# nrf7140_wificore register map
Vendor: Nordic Semiconductor; Series: nRF71; File version: 1
Registers are 32-bit, read-write, reset 0x0 unless marked. A register's access mark holds for its fields unless they carry their own. Offsets are from the block's base; [hi:lo] are bit positions; lines under a group give offsets from that group; {n}, {i} and the like mark numbered series.

## RPUPHY (part 6 of 8) — WIFICore RPU PHY peripherals
Base 0x48080000; alternate view of RPUMAC
0x10000 WLAN_TXP_TOP group — Unspecified
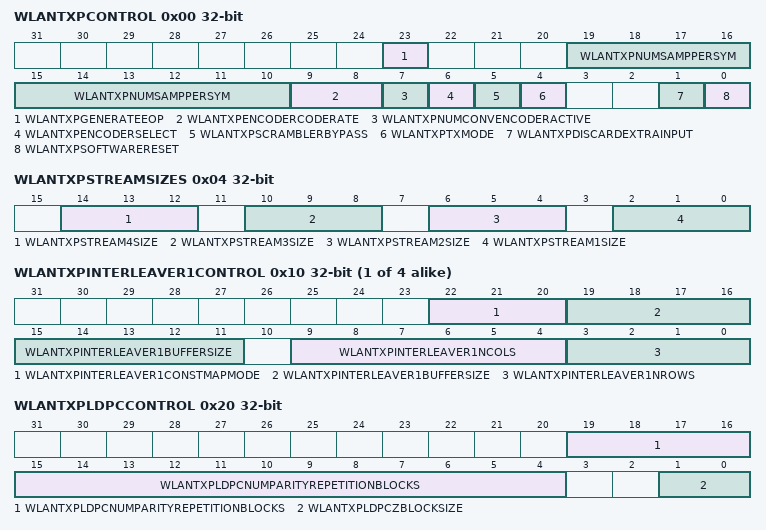
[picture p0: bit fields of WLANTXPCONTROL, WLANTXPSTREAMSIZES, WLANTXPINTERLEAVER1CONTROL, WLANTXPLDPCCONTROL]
  0x00 WLANTXPCONTROL
    [23] WLANTXPGENERATEEOP — Generate an EOP flag at the end of the packet:
      0=Don't generate an EOP flag at the end of the packet; 1=Generate an EOP flag at the end of the packet
    [19:10] WLANTXPNUMSAMPPERSYM — This is the number of samples per symbol. Represents values in the range 1 - 1024, where a value of zero written to the register would result in one sample per symbol.
    [9:8] WLANTXPENCODERCODERATE — Selects the code rate (k/n) of encoder selected from WLAN_TXP_ENCODER_SELECT. Where k is the number of information bits and n is the number of information plus parity bits.Relevant when WLAN_TXP_TX_MODE is 0.Note if WLAN_TXP_ENCODER_SELECT is 0.1) The convolutional encoder is a rate 1/2 code and appropriate puncturing is performed to bring the code rate to the desired value.2) Both convolutional encoders get same code rate.
      0=Indicates12CodeRate; 1=Indicates23CodeRate; 2=Indicates34CodeRate; 3=Indicates56CodeRate
    [7] WLANTXPNUMCONVENCODERACTIVE — Selects the number of convolutional encoders active in pipeline. Relevant when WLAN_TXP_TX_MODE is 0 and WLAN_TXP_ENCODER_SELECT is 0.Note this field is only valid if WLAN_TXP_NUM_CONV_ENCODER = 2. When WLAN_TXP_NUM_CONV_ENCODER = 1 only one convolutional encoder can be active.
      0=1 Convolution Encoder active. Convolutional Encoder Parser bypassed and only one active input to Stream Parser.; 1=2 Convolution Encoder active. Convolutional Encoder Parser alternates bits into each Convolutional Encoder. Both inputs to Stream Parser active.
    [6] WLANTXPENCODERSELECT — Selects encoding scheme to be performed. Relevant when WLAN_TXP_TX_MODE is 0.Note this field is only valid if WLAN_TXP_LDPC_ENCODER_PRESENT = 1. When WLAN_TXP_LDPC_ENCODER_PRESENT = 0 only convolutional encoding can be performed.
      0=Convolutional Encoding. Both inputs to the Stream Parser can be active depending on WLAN_TXP_NUM_CONV_ENCODER.; 1=LDPC Encoding. Only one input to the Stream Parser is active.
    [5] WLANTXPSCRAMBLERBYPASS — Causes the OFDM/DSSS scrambler to be bypassed depending on the modulation in WLAN_TXP_TX_MODE.
      0=ScramblerActive; 1=ScramblerBypassed
    [4] WLANTXPTXMODE — Selects the modulation mode for the TXP.Note DSSS/CCK Modulation is only valid when WLAN_TXP_WIFI_11B_SUPPORT = 1. In such a case the DSSS PLCP preamble and header are added to the stream.
      0=OFDM Modulation. Depending on WLAN_TXP_STREAM_*_SIZE, all WLAN_TXP_NUM_OUTPUT_STREAM number of TBus read ports can be active.; 1=DSSS/CCK Modulation. Only TBus read port 1 is active.
    [1] WLANTXPDISCARDEXTRAINPUT — Selects whether extra input after end of packet should be silently discarded.
      0=DoNotSilentlyDiscard; 1=SilentlyDiscard
    [0] WLANTXPSOFTWARERESET — This register is used to perform a software reset on the WLAN_TXP.
      0=NormalOperation; 1=ResetAsserted
  0x04 WLANTXPSTREAMSIZES
    [all] fields
      0=StreamInActive; 1=StreamSize1Bit; 2=StreamSize2Bits; 3=StreamSize3Bits; 4=StreamSize4Bits
    [14:12] WLANTXPSTREAM4SIZE — Selects the number of valid bits at the Stream 4 output of the Stream Parser. Relevant when WLAN_TXP_TX_MODE is 0.Note stream size of 4-bits is only valid if WLAN_TXP_WIFI_AC_SUPPORT = 1. Note this field is only valid if WLAN_TXP_NUM_OUTPUT_STREAM = 4.
    [10:8] WLANTXPSTREAM3SIZE — Selects the number of valid bits at the Stream 3 output of the Stream Parser. Relevant when WLAN_TXP_TX_MODE is 0.Note stream size of 4-bits is only valid if WLAN_TXP_WIFI_AC_SUPPORT = 1. Note this field is only valid if WLAN_TXP_NUM_OUTPUT_STREAM >= 3.
    [6:4] WLANTXPSTREAM2SIZE — Selects the number of valid bits at the Stream 2 output of the Stream Parser. Relevant when WLAN_TXP_TX_MODE is 0.Note stream size of 4-bits is only valid if WLAN_TXP_WIFI_AC_SUPPORT = 1. Note this field is only valid if WLAN_TXP_NUM_OUTPUT_STREAM >= 2.
    [2:0] WLANTXPSTREAM1SIZE — Selects the number of valid bits at the Stream 1 output of the Stream Parser. Relevant when WLAN_TXP_TX_MODE is 0.Note stream size of 4-bits is only valid if WLAN_TXP_WIFI_AC_SUPPORT = 1.
  0x08 WLANTXPSCRAMBLERSTATE
    [6:0] WLANTXPSCRAMBLERSTATE — OFDM or DSSS scrambler initial state. The scrambler state is pseudo-random for OFDM and fixed for DSSS. Scrambler state can be changed to any value by writing to this register.Current scrambler state can be observed by reading from register.
  0x0C WLANTXPNUMOPSYM
    [15:0] WLANTXPNUMOPSYM — Denotes the number of output symbols expected from the TXP.Represents values in the range 1 - 65536, where a value of zero written to the register would result in one symbol. The TXP will give TXP_FIELD_END indication after these many number of symbols have been given out. One symbol consists of NUM_SAMP_PER_SYM samples.
  {0xC+4j} WLANTXPINTERLEAVER{j}CONTROL (j=1..4)
    [22:20] WLANTXPINTERLEAVER{j}CONSTMAPMODE — Specifies the constellation mapping mode.Valid values are below.Other values are reserved and should not be used.000:BPSK (Constellation size M = 2) (Nbpsc = 1, Nbpsc/2 = 1 rounded up from 0.5)001:QPSK (Constellation size M = 4) (Nbpsc = 2, Nbpsc/2 = 1)010:16-QAM (Constellation size M =16) (Nbpsc = 4, Nbpsc/2 = 2)011:64-QAM (Constellation size M =64) (Nbpsc = 6, Nbpsc/2 = 3)100: 256-QAM (Constellation size M = 256) (Nbpsc = 8, Nbpsc/2 = 4)Relevant when WLAN_TXP_TX_MODE is 0. Note mapping mode of 256-QAM is only valid if WLAN_TXP_WIFI_AC_SUPPORT = 1.
    [19:11] WLANTXPINTERLEAVER{j}BUFFERSIZE — This register specifies the number of buffer storage elements required for TXP Bit Interleaver operation.Note that each buffer storage element holds Nbpsc bits of data.It is defined as WLAN_TXP_INTERLEAVER_{j}_NROWS multiplied by WLAN_TXP_INTERLEAVER_{j}_NCOLS - the value in this register is ONLY valid when it is derived from valid values in those two registers.
    [9:4] WLANTXPINTERLEAVER{j}NCOLS — This field specifies the number of active columns in the TXP Bit Interleaver (i.e. row width).Valid values are shown below; other values are reserved and should not be used.Legacy: 16HT20: 13HT40: 18VHT80:26HE: 4, 8, 13, 16, 17, 24, 26, 39Note that the maximum number of columns is 18 when WLAN_TXP_WIFI_AC_SUPPORT = 0.Relevant when WLAN_TXP_TX_MODE is 0.
    [3:0] WLANTXPINTERLEAVER{j}NROWS — This field specifies the number of active rows in the TXP Bit Interleaver.Note that each 'row' element holds Nbpsc bits of data.Valid values are shown below; other values are reserved and should not be used.Legacy: 3HT20: 4HT40: 6VHT80:9HE: 1, 3, 6, 9, 12Relevant when WLAN_TXP_TX_MODE is 0.
  0x20 WLANTXPLDPCCONTROL
    [19:4] WLANTXPLDPCNUMPARITYREPETITIONBLOCKS — Defines the number of LDPC blocks equal to or below which:1) The number of parity bits is 1 less than the value configured in WLAN_TXP_LDPC_PARITY_BITS if WLAN_TXP_LDPC_REPETITION_ACTIVE is 0.2) The number of repetition bits is 1 more than the value configured in WLAN_TXP_LDPC_REPETITION_BITS if WLAN_TXP_LDPC_REPETITION_ACTIVE is 1.Relevant when WLAN_TXP_TX_MODE is 0 and WLAN_TXP_ENCODER_SELECT is 1. Note :1) This field is only valid if WLAN_TXP_LDPC_ENCODER_PRESENT = 1.2) Represents values in the range 0 to 65535 if WLAN_TXP_WIFI_AC_SUPPORT = 1 or 0 to 1023 otherwise.
    [1:0] WLANTXPLDPCZBLOCKSIZE — Selects the Z-block size of the LDPC encoder. Relevant when WLAN_TXP_TX_MODE is 0 and WLAN_TXP_ENCODER_SELECT is 1.Note this field is only valid if WLAN_TXP_LDPC_ENCODER_PRESENT = 1.
      0=ZBlockSize27Bits; 1=ZBlockSize54Bits; 2=ZBlockSize81Bits; 3=InvalidValue
  0x24 WLANTXPLDPCNUMMESSAGEBLOCKS
    [15:0] WLANTXPLDPCNUMMESSAGEBLOCKS — Defines the number of LDPC blocks equal to or below which the number of message bits is 1 less than the value configured in WLAN_TXP_LDPC_MESSAGE_BITS. Relevant when WLAN_TXP_TX_MODE is 0 and WLAN_TXP_ENCODER_SELECT is 1.Note:1) This field is only valid if WLAN_TXP_LDPC_ENCODER_PRESENT = 1.2) Represents values in the range 0 to 65535 if WLAN_TXP_WIFI_AC_SUPPORT = 1 or 0 to 1023 otherwise.
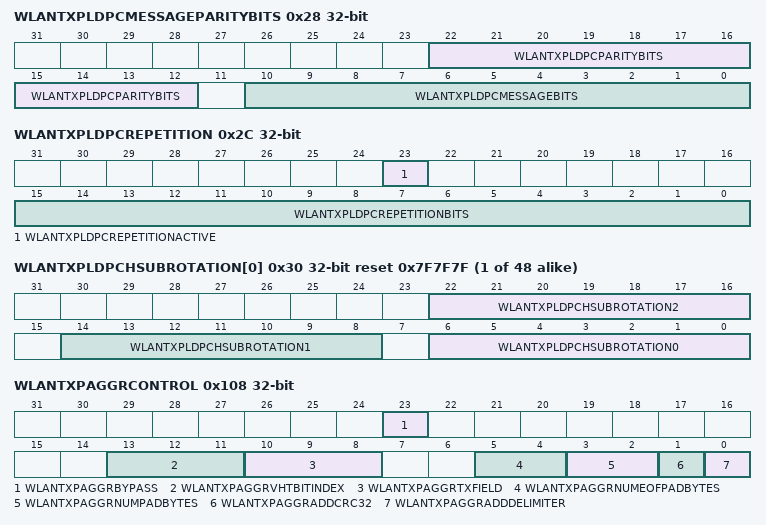
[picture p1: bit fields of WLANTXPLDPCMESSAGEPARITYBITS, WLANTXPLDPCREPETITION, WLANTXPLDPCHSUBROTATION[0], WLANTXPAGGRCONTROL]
  0x28 WLANTXPLDPCMESSAGEPARITYBITS
    [22:12] WLANTXPLDPCPARITYBITS — Defines the number of valid parity bits in (n-k) parity bits of a LDPC code word, the remaining bits are discarded. Relevant when WLAN_TXP_TX_MODE is 0 and WLAN_TXP_ENCODER_SELECT is 1.Note :1) Value written to this field and WLAN_TXP_LDPC_NUM_PARITY_REPETITION_BLOCKS should be chosen such that the number of valid parity bits lie in the range 1 to (n-k)-bits. Where the maximum value of (n-k)-bits supported by the code word can be obtained from WLAN_TXP_LDPC_Z_BLOCK_SIZE and WLAN_TXP_LDPC_CODE_RATE.2) In case WLAN_TXP_LDPC_REPETITION_ACTIVE is 1 the number of valid parity bits has to be equal to the maximum value of (n-k) bits.3) This field is only valid if WLAN_TXP_LDPC_ENCODER_PRESENT = 1.
    [10:0] WLANTXPLDPCMESSAGEBITS — Defines the number of valid message bits in k information bits of a LDPC code word, the remaining bits are zero padded in order to perform block encoding (shortening).Value written to this field and WLAN_TXP_LDPC_NUM_MESSAGE_BLOCKS should be chosen such that the number of valid message bits lie in the range 1 to k-bits. Where the maximum value of k-bits supported by the code word can be obtained from WLAN_TXP_LDPC_Z_BLOCK_SIZE and WLAN_TXP_LDPC_CODE_RATE.Relevant when WLAN_TXP_TX_MODE is 0 and WLAN_TXP_ENCODER_SELECT is 1. Note this field is only valid if WLAN_TXP_LDPC_ENCODER_PRESENT = 1.
  0x2C WLANTXPLDPCREPETITION
    [23] WLANTXPLDPCREPETITIONACTIVE — Selects if the message and parity bits need to be repeated. Relevant when WLAN_TXP_TX_MODE is 0 and WLAN_TXP_ENCODER_SELECT is 1.Note this field is only valid if WLAN_TXP_LDPC_ENCODER_PRESENT = 1.
      0=RepetitionInActive; 1=RepetitionActive
    [15:0] WLANTXPLDPCREPETITIONBITS — Defines the number of repetition bits to be given out by the LDPC encoder after the message and parity bits. Relevant when WLAN_TXP_TX_MODE is 0, WLAN_TXP_ENCODER_SELECT is 1 and WLAN_TXP_LDPC_REPETITION_ACTIVE is set to 1.Repetition starts with the first valid message bits and continues with the valid parity bits. The valid message and parity bits are resent in this order until the required number of repetition bits have been sent out of the LDPC encoder.Note:1) This field is only valid if WLAN_TXP_LDPC_ENCODER_PRESENT = 1.2) Note the value written to this field and WLAN_TXP_LDPC_NUM_PARITY_REPETITION_BLOCKS should be chosen such that the number of repetition bits lie in the range 1 to 65535 if WLAN_TXP_WIFI_AC_SUPPORT = 1 or 1 to 8191 otherwise.
  {0x30+4j} WLANTXPLDPCHSUBROTATION[{j}] (j=0..47) reset 0x7F7F7F — Description collection: WLAN TXP LDPC H SUB ROTATION
    [22:16] WLANTXPLDPCHSUBROTATION2 — Defines the amount of right cyclic shift that needs to be performed on the 3n + 2 identity sub-matrix to form the H (parity check) matrix. Valid range is 0 to the Z-block size defined by WLAN_TXP_LDPC_Z_BLOCK_SIZE. Value of 127 defines a null matrix.Relevant when WLAN_TXP_TX_MODE is 0 and WLAN_TXP_ENCODER_SELECT is 1. Note this field is only valid if WLAN_TXP_LDPC_ENCODER_PRESENT = 1.
    [14:8] WLANTXPLDPCHSUBROTATION1 — Defines the amount of right cyclic shift that needs to be performed on the 3n + 1 identity sub-matrix to form the H (parity check) matrix. Valid range is 0 to the Z-block size defined by WLAN_TXP_LDPC_Z_BLOCK_SIZE. Value of 127 defines a null matrix.Relevant when WLAN_TXP_TX_MODE is 0 and WLAN_TXP_ENCODER_SELECT is 1. Note this field is only valid if WLAN_TXP_LDPC_ENCODER_PRESENT = 1.
    [6:0] WLANTXPLDPCHSUBROTATION0 — Defines the amount of right cyclic shift that needs to be performed on the 3n identity sub-matrix to form the H (parity check) matrix. Valid range is 0 to the Z-block size defined by WLAN_TXP_LDPC_Z_BLOCK_SIZE. Value of 127 defines a null matrix.Relevant when WLAN_TXP_TX_MODE is 0 and WLAN_TXP_ENCODER_SELECT is 1. Note this field is only valid if WLAN_TXP_LDPC_ENCODER_PRESENT = 1.
  0xF4 WLANTXPAGGRMPDUDELIMITER
    [15:0] WLANTXPAGGRMPDUDELIMITER — Defines the first 16 bits of MPDU delimiter
  0xF8 WLANTXPAGGRNUMFLUSHBYTES
    [9:0] WLANTXPAGGRNUMFLUSHBYTES — Defines the number of zero flush bytes that need to be added by the TXP Aggregation module at the end of a field. Represents values in the range 0 - 1023.
  0xFC WLANTXPAGGRNUMPAYLOADBYTES
    [19:0] WLANTXPAGGRNUMPAYLOADBYTES — Defines the number of payload bytes (including 4 byte of CRC-32 if WLAN_TXP_AGGR_ADD_CRC32 is 1) that need to be sent as part of MPDU data by the TXP Aggregation.Represents values in the range 0 - 1048575.
  0x100 WLANTXPAGGRSERVICEBYTES
    [15:0] WLANTXPAGGRSERVICEBYTES — Defines the first service byte that needs to be added to the output of the TXP Aggregation module, where:1) Bits [7-0] represent the first byte which is needed to compute the descrambler initial state.2) Bits [15-8] represent the second byte which is the CRC-8 computed over VHT Sig-B field or zero for formats other than VHT.
  0x104 WLANTXPAGGRNUMNULLMPDU
    [17:0] WLANTXPAGGRNUMNULLMPDU — Defines the number of zero length MPDUs with:1) EOF set to 0 that need to be added between two consecutive MPDUs in an A-MPDU to provide the minimum MPDU Start Spacing field.2) EOF set to 1 that need to be added after the last non-zero length MPDU to provide EOF padding.Sent by the TXP Aggregation.Represents values in the range 0 - 262143.
  0x108 WLANTXPAGGRCONTROL
    [23] WLANTXPAGGRBYPASS — Causes the TXP Aggregation to be bypassed.
      0=Aggregation normal operation; 1=AggregationBypassed
    [13:11] WLANTXPAGGRVHTBITINDEX — Selects the bit index from which tail bit zero forcing of the output of the OFDM scrambler is enabled for the first flush bytes sent out of the TXP Aggregation at the end of a field.Relevant when WLAN_TXP_AGGR_TX_FIELD is 011 - 111; WLAN_TXP_ENCODER_SELECT is 0; and WLAN_TXP_AGGR_NUM_FLUSH_BYTES is not 0.Note this field is only valid if WLAN_TXP_WIFI_AC_SUPPORT = 1.
    [10:8] WLANTXPAGGRTXFIELD — Selects the field for which TXP Aggregation is being configured.Note if VHT Sig-B field is being processed the input data is sent to the TXP Aggregation circular buffer. TXP Aggregation should only receive 4 input bytes in this case.Note this field is only valid if WLAN_TXP_WIFI_AC_SUPPORT = 1.
      0=Legacy or HT (High Throughput) fields; 3=VHT (Very High Throughput) all other fields; 4=VhtVeryHighThroughp4 (VHT (Very High Throughput) Sig-B field20 MHz,4 bytes taken out of the TXP Aggregation.); 5=VhtVeryHighThroughp5 (VHT (Very High Throughput) Sig-B field40 MHz,7 bytes taken out of the TXP Aggregation.); 6=VhtVeryHighThroughp6 (VHT (Very High Throughput) Sig-B field80 MHz, 15 bytes taken out of the TXP Aggregation.); 7=VhtVeryHighThroughp7 (VHT (Very High Throughput) Sig-B field 160 MHz, 30 bytes taken out of the TXP Aggregation.)
    [5:4] WLANTXPAGGRNUMEOFPADBYTES — Defines the number of zero pad bytes that need to be appended after the last A-MPDU sub-frame by the TXP Aggregation to make A-MPDU length equal to PSDU length or a multiple of 4, whichever occurs first.Represents values in the range 0 - 3.
    [3:2] WLANTXPAGGRNUMPADBYTES — Defines the number of zero pad bytes that need to be appended after the MPDU data for all A-MPDU sub-frames by the TXP Aggregation, except the last one, so that the (WLAN_TXP_AGGR_NUM_PAYLOAD_BYTES + WLAN_TXP_AGGR_NUM_PAD_BYTES) is a multiple of 4.Represents values in the range 0 - 3.
    [1] WLANTXPAGGRADDCRC32 — Enable or Disable CRC-32 computation on the MPDU data in the TXP Aggregation.
      0=Crc32NotComputed; 1=CRC-32 computed and appended after payload
    [0] WLANTXPAGGRADDDELIMITER — Defines whether MPDU Delimiter needs to be transferred before MPDU data to form an A-MPDU subframe by the TXP Aggregation.
      0=MPDU Delimiter not transferred; 1=MPDU Delimiter transferred
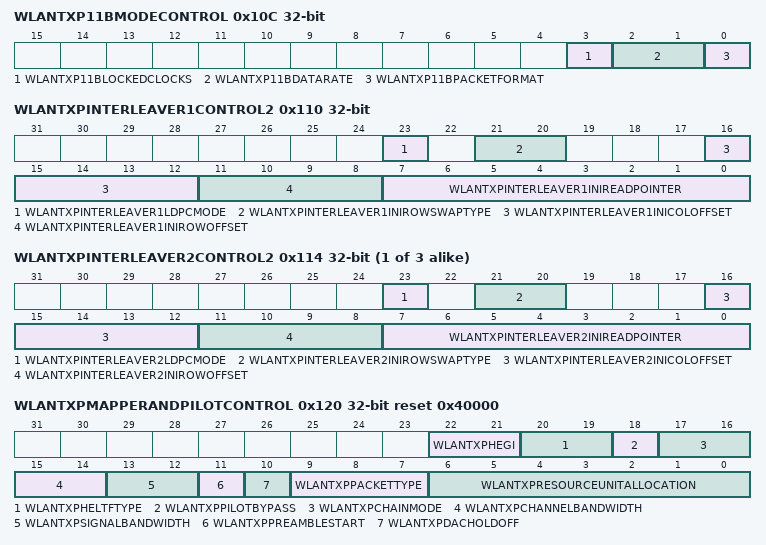
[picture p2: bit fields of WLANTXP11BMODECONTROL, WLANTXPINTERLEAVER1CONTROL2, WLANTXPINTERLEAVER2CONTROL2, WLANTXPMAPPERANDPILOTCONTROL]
  0x10C WLANTXP11BMODECONTROL
    [3] WLANTXP11BLOCKEDCLOCKS — Indicates that the transmit frequency and symbol clocks are derived from the same oscillator. This bit shall be set by the PHY layer based on its implementation configuration.
    [2:1] WLANTXP11BDATARATE — Selects the transmission data rate.Note this field is only valid if WLAN_TXP_WIFI_11B_SUPPORT = 1.
      0=1Mbps; 1=2Mbps; 2=55Mbps; 3=11Mbps
    [0] WLANTXP11BPACKETFORMAT — Selects the 802.11b data packet format.Note this field is only valid if WLAN_TXP_WIFI_11B_SUPPORT = 1.
      0=LongDataPacketFormat; 1=Short data packet format
  0x110 WLANTXPINTERLEAVER1CONTROL2
    [23] WLANTXPINTERLEAVER1LDPCMODE — Defines the data processing mode when WLAN_TXP_ENCODER_SELECT=1 (i.e. LDPC Encoder is selected).When WLAN_TXP_ENCODER_SELECT=0 this register setting is not relevant.
      0=LDPC Tone Mapping not enabled.Bypass the Interleaver logic such that received data is output unmodified (i.e. non-VHT frames); 1=LDPC Tone Mapping enabled.Apply LDPC Tone Mapping to data received in the Interleaver as configured in register WLAN_TXP_INTERLEAVER_n_CONTROL (i.e. VHT frames).
    [21:20] WLANTXPINTERLEAVER1INIROWSWAPTYPE — Registers WLAN_TXP_INTERLEAVER_n_INI_ROW_SWAP_TYPE/INI_COL_OFFSET/INI_ROW_OFFSET/INI_READ_POINTER control Stage 3 interleaving.To turn off Hardware Stage 3 interleaving set all four registers to 0.To turn on Hardware Stage 3 interleaving configure all four registers correctly with non-zero values.This register is used to specify the row swapping type in use in the column WLAN_TXP_INTERLEAVER_n_INI_COL_OFFSET.It is only used when the modulation, set in register WLAN_TXP_INTERLEAVER_n_CONST_MAP_MODE, is set to a modulation scheme that requires row swapping - i.e. not BPSK (Nbpsc = 1) or QPSK (Nbpsc = 2).The value in this register is calculated as follows:For16-QAM (Nbpsc = 4): WLAN_TXP_INTERLEAVER_n_INI_COL_OFFSET percent2i.e. 0x0 when WLAN_TXP_INTERLEAVER_n_INI_COL_OFFSET is an even number0x1 when WLAN_TXP_INTERLEAVER_n_INI_COL_OFFSET is an odd numberFor64-QAM (Nbpsc = 6): WLAN_TXP_INTERLEAVER_n_INI_COL_OFFSET percent3i.e. 0x0 when WLAN_TXP_INTERLEAVER_n_INI_COL_OFFSET is 0,3,6, 9,12,etc0x1 when WLAN_TXP_INTERLEAVER_n_INI_COL_OFFSET is 1,4,7,10,13,etc0x2 when WLAN_TXP_INTERLEAVER_n_INI_COL_OFFSET is 2,5,8,11,14,etcFor 256-QAM (Nbpsc = 8): WLAN_TXP_INTERLEAVER_n_INI_COL_OFFSET percent4i.e. 0x0 when WLAN_TXP_INTERLEAVER_n_INI_COL_OFFSET is 0,4, 8,12,etc0x1 when WLAN_TXP_INTERLEAVER_n_INI_COL_OFFSET is 1,5, 9,13,etc0x2 when WLAN_TXP_INTERLEAVER_n_INI_COL_OFFSET is 2,6,10,14,etc0x3 when WLAN_TXP_INTERLEAVER_n_INI_COL_OFFSET is 3,7,11,15,etc
    [16:12] WLANTXPINTERLEAVER1INICOLOFFSET — Registers WLAN_TXP_INTERLEAVER_n_INI_ROW_SWAP_TYPE/INI_COL_OFFSET/INI_ROW_OFFSET/INI_READ_POINTER control Stage 3 interleaving.To turn off Hardware Stage 3 interleaving set all four registers to 0.To turn on Hardware Stage 3 interleaving configure all four registers correctly with non-zero values.Stage 3 Interleaver, Initial Column offset.This is the column which holds the first Nbpsc read bits after rotation has been applied.Note that a Column is made up of elements, each element holds Nbpsc bits.Note 1. WLAN_TXP_INTERLEAVER_n_INI_COL_OFFSET has the range 0 to WLAN_TXP_INTERLEAVER_n_NCOLS-1.Note 2. The valid values for this register can be found in the HW TRM, see section 7.4.9 (TXP Interleaver).These are derived from the Row Offset equation in the same location.
    [11:8] WLANTXPINTERLEAVER1INIROWOFFSET — Registers WLAN_TXP_INTERLEAVER_n_INI_ROW_SWAP_TYPE/INI_COL_OFFSET/INI_ROW_OFFSET/INI_READ_POINTER control Stage 3 interleaving.To turn off Hardware Stage 3 interleaving set all four registers to 0.To turn on Hardware Stage 3 interleaving configure all four registers correctly with non-zero values.Stage 3 Interleaver, Initial Row Offset. This is the row which holds the first Nbpsc read bits after rotation has been applied.Note that a Row is made up of elements, each element holds Nbpsc bits.Row Offset is computed from the equation in section 2.2.3 (Third interleaver stage), is given in Table 3.Note 1. WLAN_TXP_INTERLEAVER_n_INI_ROW_OFFSET has the range 0 to WLAN_TXP_INTERLEAVER_n_NROWS-1Note 2. The valid values for this register can be found in the HW TRM, see section 7.4.9 (TXP Interleaver).These are derived from the Row Offset equation in the same location.
    [7:0] WLANTXPINTERLEAVER1INIREADPOINTER — Registers WLAN_TXP_INTERLEAVER_n_INI_ROW_SWAP_TYPE/INI_COL_OFFSET/INI_ROW_OFFSET/INI_READ_POINTER control Stage 3 interleaving.To turn off Hardware Stage 3 interleaving set all four registers to 0.To turn on Hardware Stage 3 interleaving configure all four registers correctly with non-zero values.This register specifies the initial value of the read pointer for reading the first element of bits from the read buffer.The value in this register is calculated as follows:((WLAN_TXP_INTERLEAVER_n_INI_ROW_OFFSET * WLAN_TXP_INTERLEAVER_n_NCOLS) + WLAN_TXP_INTERLEAVER_n_INI_COL_OFFSET)
  {0x10C+4j} WLANTXPINTERLEAVER{j}CONTROL2 (j=2..4)
    [23] WLANTXPINTERLEAVER{j}LDPCMODE — For description see WLAN_TXP_INTERLEAVER_1_LDPC_MODE
    [21:20] WLANTXPINTERLEAVER{j}INIROWSWAPTYPE — For description see WLAN_TXP_INTERLEAVER_1_INI_ROW_SWAP_TYPE
    [16:12] WLANTXPINTERLEAVER{j}INICOLOFFSET — For description see WLAN_TXP_INTERLEAVER_1_INI_COL_OFFSET
    [11:8] WLANTXPINTERLEAVER{j}INIROWOFFSET — For description see WLAN_TXP_INTERLEAVER_1_INI_ROW_OFFSET
    [7:0] WLANTXPINTERLEAVER{j}INIREADPOINTER — For description see WLAN_TXP_INTERLEAVER_1_INI_READ_POINTER
  0x120 WLANTXPMAPPERANDPILOTCONTROL reset 0x40000
    [22:21] WLANTXPHEGI — Guard interval for HE frames.
      0=08Us; 1=16Us; 2=32Us
    [20:19] WLANTXPHELTFTYPE — Type of HE-LTF preamble. For HE formats only.
      0=1XHeLtf; 1=2XHeLtf; 2=4XHeLtf
    [18] WLANTXPPILOTBYPASS — Pilots insertion control.
      0=InsertPilots; 1=Bypass
    [17:16] WLANTXPCHAINMODE — Selects chain mode. HT-packets only.0 : 1x11 : 2x2 (chain 1)2 : 2x2 (chain 2)3 : reservedIt determines the sign of pilots.
    [15:14] WLANTXPCHANNELBANDWIDTH — Selects samples per symbolNOTE: Channel bandwidth can have different value than signal bandwidth in case of Legacy packet type.For Legacy packet type signal bandwidth will always be 20MHz. In this case if channel bandwidth isset to 40MHz Legacy packet will be duplicated and if channel bandwidth is set to 80MHz Legacy packetwill be copied over four segments. Duplication will be handled after TXP (IFFT) and TXP will performcoresponding scaling of I and Q components (over 52, 104 or 208 non-null sub-carriers).Channel bandwidth is not auto-configured and it should be configured to STA Operating bandwidth.
      0=20Mhz; 1=40Mhz; 2=80Mhz; 3=Reserve (This is reserved.)
    [13:12] WLANTXPSIGNALBANDWIDTH — Selects samples per symbolNOTE: signal_bandwidth can have different value than channel bandwidth.Please sse the note for the WLAN_TXP_CHANNEL_BANDWIDTH field.
      0=20Mhz; 1=40Mhz; 2=80Mhz; 3=Reserve (This is reserved.)
    [11] WLANTXPPREAMBLESTART — Selects condition to start the preamble generator
      0=Start preamble generator after first byte of TX vector is received; 1=StartPreambleGenerat1 (Start preamble generator after first payload byte after the AMPDU delimiter is received)
    [10] WLANTXPDACHOLDOFF — Selects DAC output hold-off
      0=DAC output hold-off specified by WLAN_CTRL_TX_HOLDOFF; 1=DacOutputHoldOffSpe1 (DAC output hold-off specified by WLAN_CTRL_TX_HOLDOFF+WLAN_CTRL_TX_EXTRA_HOLDOFF)
    [9:7] WLANTXPPACKETTYPE — Selects packet type:0 : Legacy1 : HT_MF2 : HT_GF3 : VHT4 : HE_SU5 : HE_MU6 : HE_ER_SU7 : HE_TBPackets 0-3 (Legacy, HT_MF, HT_GF, VHT) are in Pre-HE group with OFDM symbollength of 3.2us. HE packets have 12.8us OFDM symbol length.
    [6:0] WLANTXPRESOURCEUNITALLOCATION — Used to determine the number of non null sub-carriers.Valid ranges of values are [0-8, 9-17, 37-40, 41-44, 53-56, 61-62, 65].Only applicable for HE packets.
  0x124 WLANTXPEVENTSTATUS
    [0] WLANTXPFIELDENDSTATUS — This field indicates the current status of the txp_field_end event. Value of 1 indicates field has ended. Write any value to register to clear flag.
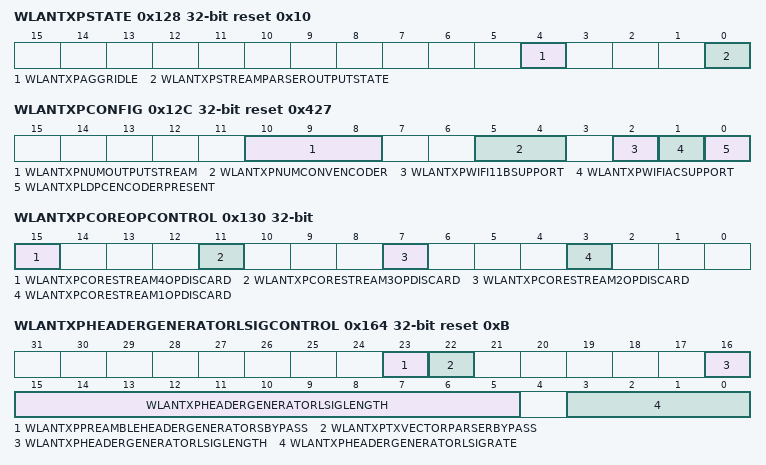
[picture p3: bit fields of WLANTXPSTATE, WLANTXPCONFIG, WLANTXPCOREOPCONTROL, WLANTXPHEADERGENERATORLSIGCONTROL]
  0x128 WLANTXPSTATE ro reset 0x10
    [4] WLANTXPAGGRIDLE — This is a read-only field. Value read out indicates the state of the TXP Aggregation.0: Aggregation busy, should not be reconfigured to process next job.1: Aggregation idle, can be reconfigured to process next job.Writing to field would not change its value.
    [0] WLANTXPSTREAMPARSEROUTPUTSTATE — This is a read-only field. Value read out indicates the output state of the Stream Parser in the TXP Core.0: Output enabled, normal operation.1: Output disabled after required symbols and samples have been sent out. Re-enable by asserting a soft or hard reset on the entire TXP (this will also reset any data in the pipeline).Writing to field would not change its value.
  0x12C WLANTXPCONFIG ro reset 0x427
    [10:8] WLANTXPNUMOUTPUTSTREAM — This is a read-only field. Value read out indicates the number of output streams present in the TXP. Writing to field would not change its value.
    [5:4] WLANTXPNUMCONVENCODER — This is a read-only field. Value read out indicates the number of convolutional encoders present in the TXP. Writing to field would not change its value.
    [2] WLANTXPWIFI11BSUPPORT — This is a read-only field. Value read out indicates 802.11b support in the TXP.0: 802.11b not supported.1: 802.11b supported.Writing to field would not change its value.
    [1] WLANTXPWIFIACSUPPORT — This is a read-only field. Value read out indicates 802.11ac support in the TXP.0: 802.11ac not supported.1: 802.11ac supported.Writing to field would not change its value.
    [0] WLANTXPLDPCENCODERPRESENT — This is a read-only field. Value read out indicates the presence of the LDPC encoder in the TXP.0: LDPC encoder not present.1: LDPC encoder present.Writing to field would not change its value.
  0x130 WLANTXPCOREOPCONTROL
    [all] fields
      0=Output to PBus (debug mode); 1=DiscardOutput
    [15] WLANTXPCORESTREAM4OPDISCARD — Discard debug mode output when WLAN_TXP_CORE_STREAM_4_OP_MODE = 1:Note this field is only valid if WLAN_TXP_NUM_OUTPUT_STREAM = 4.
    [11] WLANTXPCORESTREAM3OPDISCARD — Discard debug mode output when WLAN_TXP_CORE_STREAM_3_OP_MODE = 1:Note this field is only valid if WLAN_TXP_NUM_OUTPUT_STREAM >= 3.
    [7] WLANTXPCORESTREAM2OPDISCARD — Discard debug mode output when WLAN_TXP_CORE_STREAM_2_OP_MODE = 1:Note this field is only valid if WLAN_TXP_NUM_OUTPUT_STREAM >= 2.
    [3] WLANTXPCORESTREAM1OPDISCARD — Discard debug mode output when WLAN_TXP_CORE_STREAM_1_OP_MODE = 1:
  {0x130+0xC*j} WLANTXPCORESTREAM{j}OPSIGNATURE ro reset 0xFFFFFF (j=1..4)
    [23:0] WLANTXPCORESTREAM{j}OPSIGNATURE — Debug signature from TXP Core Stream {j} output.
  0x164 WLANTXPHEADERGENERATORLSIGCONTROL reset 0xB
    [23] WLANTXPPREAMBLEHEADERGENERATORSBYPASS — If set to 1, bypass both the preamble and header generators.
    [22] WLANTXPTXVECTORPARSERBYPASS — If set to 1, bypass the Tx Vector Parser.
    [16:5] WLANTXPHEADERGENERATORLSIGLENGTH — The value of the L-SIG length field, only used if WLAN_TXP_TX_MODE is 0.
    [3:0] WLANTXPHEADERGENERATORLSIGRATE — The value of the L-SIG rate field, only used if WLAN_TXP_TX_MODE is 0.
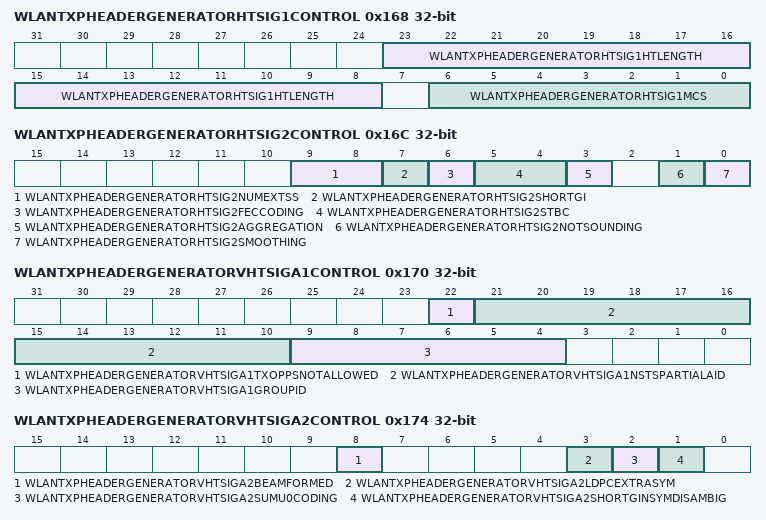
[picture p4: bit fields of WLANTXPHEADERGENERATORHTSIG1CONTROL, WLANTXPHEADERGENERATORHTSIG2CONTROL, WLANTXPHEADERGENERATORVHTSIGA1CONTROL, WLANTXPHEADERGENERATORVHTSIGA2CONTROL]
  0x168 WLANTXPHEADERGENERATORHTSIG1CONTROL
    [23:8] WLANTXPHEADERGENERATORHTSIG1HTLENGTH — The value of the HT-SIG1 HT length field, only used if WLAN_TXP_TX_MODE is 0and WLAN_TXP_PACKET_TYPE is 1 or 5.
    [6:0] WLANTXPHEADERGENERATORHTSIG1MCS — The value of the HT-SIG1 MCS field, only used if WLAN_TXP_TX_MODE is 0and WLAN_TXP_PACKET_TYPE is 1 or 5.Note this field is also used for the VHT header, i.e. ifWLAN_TXP_PACKET_TYPE is 2.
  0x16C WLANTXPHEADERGENERATORHTSIG2CONTROL
    [9:8] WLANTXPHEADERGENERATORHTSIG2NUMEXTSS — The value of the HT-SIG2 Number of Extension Spatial Streams field,only used if WLAN_TXP_TX_MODE is 0 and WLAN_TXP_PACKET_TYPE is 1 or 5.
    [7] WLANTXPHEADERGENERATORHTSIG2SHORTGI — The value of the HT-SIG2 Short GI field, only used if WLAN_TXP_TX_MODE is 0and WLAN_TXP_PACKET_TYPE is 1 or 5.Note this field is also used for the VHT header, i.e. ifWLAN_TXP_PACKET_TYPE is 2.
    [6] WLANTXPHEADERGENERATORHTSIG2FECCODING — The value of the HT-SIG2 FEC Coding field, only used if WLAN_TXP_TX_MODE is 0and WLAN_TXP_PACKET_TYPE is 1 or 5.
    [5:4] WLANTXPHEADERGENERATORHTSIG2STBC — The value of the HT-SIG2 STBC field, only used if WLAN_TXP_TX_MODE is 0and WLAN_TXP_PACKET_TYPE is 1 or 5.
    [3] WLANTXPHEADERGENERATORHTSIG2AGGREGATION — The value of the HT-SIG2 Aggregation field, only used if WLAN_TXP_TX_MODE is 0and WLAN_TXP_PACKET_TYPE is 1 or 5.
    [1] WLANTXPHEADERGENERATORHTSIG2NOTSOUNDING — The value of the HT-SIG2 Not Sounding field, only used if WLAN_TXP_TX_MODE is 0and WLAN_TXP_PACKET_TYPE is 1 or 5.
    [0] WLANTXPHEADERGENERATORHTSIG2SMOOTHING — The value of the HT-SIG2 Smoothing field, only used if WLAN_TXP_TX_MODE is 0and WLAN_TXP_PACKET_TYPE is 1 or 5.
  0x170 WLANTXPHEADERGENERATORVHTSIGA1CONTROL
    [22] WLANTXPHEADERGENERATORVHTSIGA1TXOPPSNOTALLOWED — The value of the VHT-SIG-A1 TXOP PS Not Allowed field,only used if WLAN_TXP_TX_MODE is 0 and WLAN_TXP_PACKET_TYPE is 3.
    [21:10] WLANTXPHEADERGENERATORVHTSIGA1NSTSPARTIALAID — The value of the VHT-SIG-A1 NSTS Partial Aid field,only used if WLAN_TXP_TX_MODE is 0 and WLAN_TXP_PACKET_TYPE is 3.
    [9:4] WLANTXPHEADERGENERATORVHTSIGA1GROUPID — The value of the VHT-SIG-A1 Group ID field,only used if WLAN_TXP_TX_MODE is 0 and WLAN_TXP_PACKET_TYPE is 3.
  0x174 WLANTXPHEADERGENERATORVHTSIGA2CONTROL
    [8] WLANTXPHEADERGENERATORVHTSIGA2BEAMFORMED — The value of the VHT-SIG-A2 Beamformed field,only used if WLAN_TXP_TX_MODE is 0 and WLAN_TXP_PACKET_TYPE is 3.
    [3] WLANTXPHEADERGENERATORVHTSIGA2LDPCEXTRASYM — The value of the VHT-SIG-A2 LDPC Extra Symbol field,only used if WLAN_TXP_TX_MODE is 0 and WLAN_TXP_PACKET_TYPE is 3.
    [2] WLANTXPHEADERGENERATORVHTSIGA2SUMU0CODING — The value of the VHT-SIG-A2 Single User / Multi User 0 Coding field,only used if WLAN_TXP_TX_MODE is 0 and WLAN_TXP_PACKET_TYPE is 3.
    [1] WLANTXPHEADERGENERATORVHTSIGA2SHORTGINSYMDISAMBIG — The value of the VHT-SIG-A2 Short GI Number of Symbols Disambiguation field,only used if WLAN_TXP_TX_MODE is 0 and WLAN_TXP_PACKET_TYPE is 3.
  0x178 WLANTXPHEADERGENERATORVHTSIGBCONTROL
    [20:0] WLANTXPHEADERGENERATORVHTSIGBLENGTH — Length field in the VHT-SIG-B header, equal to ceil(APEP length / 4)where APEP length comes from the Tx Vector.For 20 MHz only the least-significant 17 bits are used.For 40 MHz only the least-significant 19 bits are used.Only used if WLAN_TXP_TX_MODE is 0 and WLAN_TXP_PACKET_TYPE is 3.
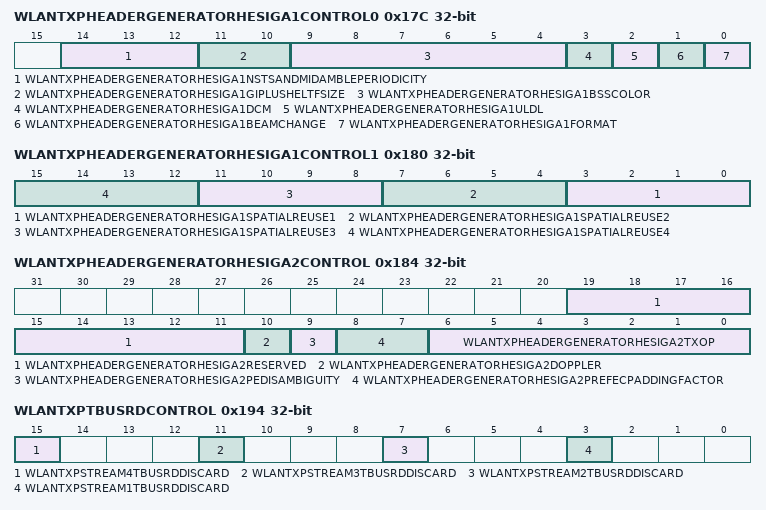
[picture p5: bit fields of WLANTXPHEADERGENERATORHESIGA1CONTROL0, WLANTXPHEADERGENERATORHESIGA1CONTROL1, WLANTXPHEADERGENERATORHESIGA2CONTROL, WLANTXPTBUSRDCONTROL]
  0x17C WLANTXPHEADERGENERATORHESIGA1CONTROL0
    [14:12] WLANTXPHEADERGENERATORHESIGA1NSTSANDMIDAMBLEPERIODICITY — The value of the HE-SIG-A1 NSTS_AND_MIDAMBLE_PERIODICITY field,only used if WLAN_TXP_TX_MODE is 0 and WLAN_TXP_PACKET_TYPE is 4 or up.
    [11:10] WLANTXPHEADERGENERATORHESIGA1GIPLUSHELTFSIZE — The value of the HE-SIG-A1 GI_PLUS_HE_LTF_SIZE field,only used if WLAN_TXP_TX_MODE is 0 and WLAN_TXP_PACKET_TYPE is 4 or up.
    [9:4] WLANTXPHEADERGENERATORHESIGA1BSSCOLOR — The value of the HE-SIG-A1 BSS_COLOR field,only used if WLAN_TXP_TX_MODE is 0 and WLAN_TXP_PACKET_TYPE is 4 or up.
    [3] WLANTXPHEADERGENERATORHESIGA1DCM — The value of the HE-SIG-A1 DCM field,only used if WLAN_TXP_TX_MODE is 0 and WLAN_TXP_PACKET_TYPE is 4 or up.
    [2] WLANTXPHEADERGENERATORHESIGA1ULDL — The value of the HE-SIG-A1 UL_DL field,only used if WLAN_TXP_TX_MODE is 0 and WLAN_TXP_PACKET_TYPE is 4 or up.
    [1] WLANTXPHEADERGENERATORHESIGA1BEAMCHANGE — The value of the HE-SIG-A1 BEAM_CHANGE field,only used if WLAN_TXP_TX_MODE is 0 and WLAN_TXP_PACKET_TYPE is 4 or up.
    [0] WLANTXPHEADERGENERATORHESIGA1FORMAT — The value of the HE-SIG-A1 FORMAT field,only used if WLAN_TXP_TX_MODE is 0 and WLAN_TXP_PACKET_TYPE is 4 or up.
  0x180 WLANTXPHEADERGENERATORHESIGA1CONTROL1
    [4n-1:4n-4] WLANTXPHEADERGENERATORHESIGA1SPATIALREUSE{n} (n=1..4) — The value of the HE-SIG-A1 SPATIAL_REUSE_{n} field,only used if WLAN_TXP_TX_MODE is 0 and WLAN_TXP_PACKET_TYPE is 4 or up.
  0x184 WLANTXPHEADERGENERATORHESIGA2CONTROL
    [19:11] WLANTXPHEADERGENERATORHESIGA2RESERVED — The value of the HE-SIG-A2 RESERVED field,only used if WLAN_TXP_TX_MODE is 0 and WLAN_TXP_PACKET_TYPE is 4 or up.
    [10] WLANTXPHEADERGENERATORHESIGA2DOPPLER — The value of the HE-SIG-A1 DOPPLER field,only used if WLAN_TXP_TX_MODE is 0 and WLAN_TXP_PACKET_TYPE is 4 or up.
    [9] WLANTXPHEADERGENERATORHESIGA2PEDISAMBIGUITY — The value of the HE-SIG-A2 PE_DISAMBIGUITY field,only used if WLAN_TXP_TX_MODE is 0 and WLAN_TXP_PACKET_TYPE is 4 or up.
    [8:7] WLANTXPHEADERGENERATORHESIGA2PREFECPADDINGFACTOR — The value of the HE-SIG-A1 PRE_FEC_PADDING_FACTORfield,only used if WLAN_TXP_TX_MODE is 0 and WLAN_TXP_PACKET_TYPE is 4 or up.
    [6:0] WLANTXPHEADERGENERATORHESIGA2TXOP — The value of the HE-SIG-A2 TXOP field,only used if WLAN_TXP_TX_MODE is 0 and WLAN_TXP_PACKET_TYPE is 4 or up.
  0x18C WLANTXPPREFECPADPHY
    [3:0] WLANTXPPREFECPADPHY — Remainder of num_pad_bits/8.
  0x190 WLANTXPPOSTFECCONTROL0
    [0] WLANTXPPOSTFECBYPASS — If set to 1, bypass the post-FEC padder.
  0x194 WLANTXPTBUSRDCONTROL
    [all] fields
      0=Output to PBus (debug mode); 1=DiscardOutput
    [15] WLANTXPSTREAM4TBUSRDDISCARD — Discard PBus debug mode output when WLAN_TXP_STREAM_4_TBUS_RD_MODE = 1:Note this field is only valid if WLAN_TXP_NUM_OUTPUT_STREAM = 4.
    [11] WLANTXPSTREAM3TBUSRDDISCARD — Discard PBus debug mode output when WLAN_TXP_STREAM_3_TBUS_RD_MODE = 1:Note this field is only valid if WLAN_TXP_NUM_OUTPUT_STREAM >= 3.
    [7] WLANTXPSTREAM2TBUSRDDISCARD — Discard PBus debug mode output when WLAN_TXP_STREAM_2_TBUS_RD_MODE = 1:Note this field is only valid if WLAN_TXP_NUM_OUTPUT_STREAM >= 2.
    [3] WLANTXPSTREAM1TBUSRDDISCARD — Discard PBus debug mode output when WLAN_TXP_STREAM_1_TBUS_RD_MODE = 1:
  0x198 WLANTXPPOSTFECBITSBEFOREPADLSB
    [23:0] WLANTXPPOSTFECBITSBEFOREPADLSB — Number of data bits before the post-FEC padding - LSB
  0x19C WLANTXPPOSTFECBITSBEFOREPADMSB
    [0] WLANTXPPOSTFECBITSBEFOREPADMSB — Number of data bits before the post-FEC padding - MSB
  0x1A0 WLANTXPPOSTFECBITSAFTERPADLSB
    [23:0] WLANTXPPOSTFECBITSAFTERPADLSB — Number of data bits after the post-FEC padding - LSB
  0x1A4 WLANTXPPOSTFECBITSAFTERPADMSB
    [0] WLANTXPPOSTFECBITSAFTERPADMSB — Number of data bits after the post-FEC padding - MSB
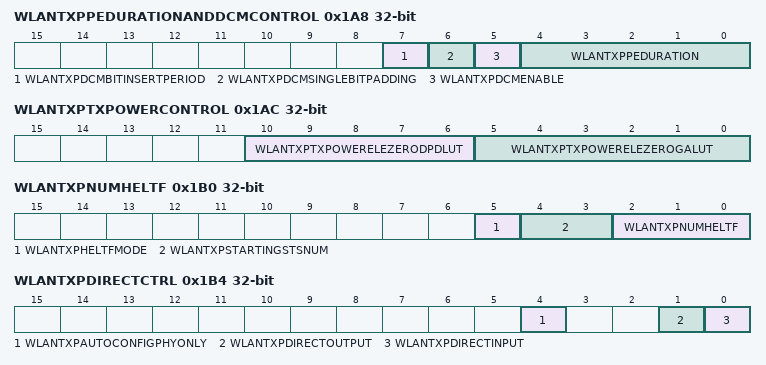
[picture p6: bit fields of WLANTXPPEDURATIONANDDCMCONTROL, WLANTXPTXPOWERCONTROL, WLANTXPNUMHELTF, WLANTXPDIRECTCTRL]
  0x1A8 WLANTXPPEDURATIONANDDCMCONTROL
    [7] WLANTXPDCMBITINSERTPERIOD — Period at which the zero bit is inserted.Relevant only if WLAN_TXP_DCM_SINGLE_BIT_PADDING is 1.
      0=Every50Bits; 1=Every116Bits
    [6] WLANTXPDCMSINGLEBITPADDING — If set to 1, enable single-bit padding in BPSK bitstream every WLAN_TXP_DCM_BIT_INSERT_PERIOD bits.
    [5] WLANTXPDCMENABLE — If set to 1, enable Dual Carrier Modulation.
    [4:0] WLANTXPPEDURATION — Packet Extension Duration in microseconds
  0x1AC WLANTXPTXPOWERCONTROL
    [10:6] WLANTXPTXPOWERELEZERODPDLUT — TX power value for which DPD coefficient values are stored in 0th index of LUT.Value is in dBm and it can be in the range of -10dBm to +10dBm.
    [5:0] WLANTXPTXPOWERELEZEROGALUT — TX power value for which IQ imbalance values are stored in 0th index of Gain Angle LUT.Value is in dBm and it can be in the range of -10dBm to +20dBm.
  0x1B0 WLANTXPNUMHELTF
    [5] WLANTXPHELTFMODE — HE-LTF mode.
    [4:3] WLANTXPSTARTINGSTSNUM — Starting STS number.
    [2:0] WLANTXPNUMHELTF — Number of HE-LTF symbols. Encoded as follows:0: 11: 22: 43: 64: 85-7: Reserved
  0x1B4 WLANTXPDIRECTCTRL
    [4] WLANTXPAUTOCONFIGPHYONLY — Defines auto-configuration for WLAN_TXP_DIRECT_INPUT:
      0=TXP input comes from previous pipeline stage (i.e. MAC).; 1=TXP input comes from EDC (tbus)
    [1] WLANTXPDIRECTOUTPUT — Selects whether TXP output goes to next pipeline stage or EDC (tbus).
      0=Tbus; 1=Direct
    [0] WLANTXPDIRECTINPUT — Selects whether TXP input comes from previous pipeline stage or EDC (tbus).
      0=Tbus; 1=Direct
  0x1F0 WLANTXPDEBUG
    [1:0] WLANTXPDEBUG — Enable debug registers WLAN_TXP_DEBUG_VALID and WLAN_TXP_DEBUG_ENABLE
      0=Disabled; 1=ValidEnable; 2=Sticky(Valid), Sticky(Enable); 3=Valid & Enable, Sticky(Valid & Enable)
  0x1F4 WLANTXPDEBUGVALID ro
    [22:0] WLANTXPDEBUGVALID — Live state of the valid flow control signals0: TXP WR1: Vector Parser Output2: Header Generator Output3: Preamble Generator Output4: Aggregation Input5: DSSS PLCP Input6: TXP Core Input7: DSSS Input8: DSSS Output9: Scrambler Output10: BCC Encoder Output11: Post-FEC Padding Output12: HE-ER-SU Logic Output13: Repacker Output14: DCM Logic Output15: Stream Parser Output16: ODFM Modulator Input17: Interleaver Input18: Interleaver Output19: Mapper Input20: Mapper Output21: Pilot Insertion Output22: TXP RD
  0x1F8 WLANTXPDEBUGENABLE ro
    [22:0] WLANTXPDEBUGENABLE — Live state of the enable flow control signals0: TXP WR1: Vector Parser Output2: Header Generator Output3: Preamble Generator Output4: Aggregation Input5: DSSS PLCP Input6: TXP Core Input7: DSSS Input8: DSSS Output9: Scrambler Output10: BCC Encoder Output11: Post-FEC Padding Output12: HE-ER-SU Logic Output13: Repacker Output14: DCM Logic Output15: Stream Parser Output16: ODFM Modulator Input17: Interleaver Input18: Interleaver Output19: Mapper Input20: Mapper Output21: Pilot Insertion Output22: TXP RD
  0x1FC WLANTXPDEBUGSIDEBAND ro
    [3:0] WLANTXPDEBUGSIDEBAND — Live state of the sideband signal
      0=DataField; 1=LStf; 2=LLtf; 3=HT-STF for HT format, HE-STF for HE formats; 4=HT-LTF1 for HT format, HE-LTF for HE formats; 9=LSig; 10=HtSig; 11=VhtSigA1; 12=VhtSigA2; 13=VhtSigB20Mhz; 14=VhtSigB40Mhz; 15=HeSigA
